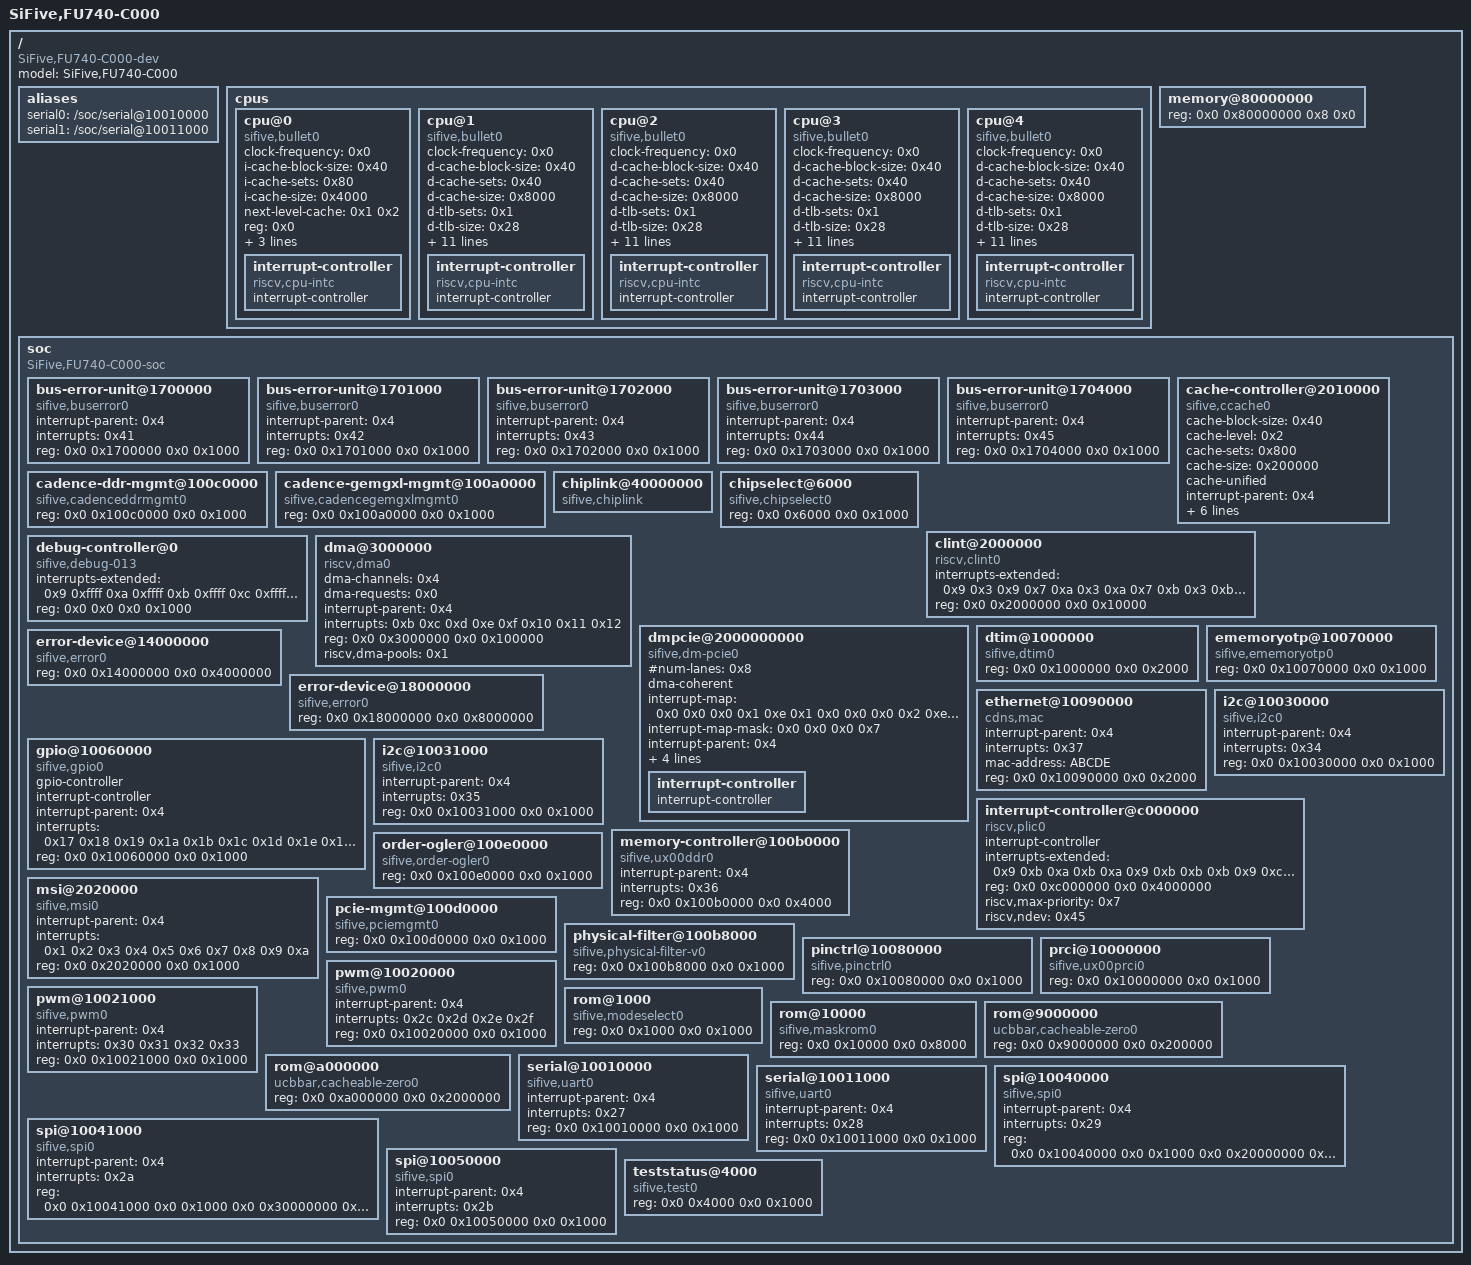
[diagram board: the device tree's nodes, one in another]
/dts-v1/;

/ {
	#address-cells = <0x2>;
	#size-cells = <0x2>;
	compatible = "SiFive,FU740-C000-dev", "fu700-dev", "sifive-dev";
	model = "SiFive,FU740-C000";

	aliases {
		serial0 = "/soc/serial@10010000";
		serial1 = "/soc/serial@10011000";
	};

	cpus {
		#address-cells = <0x1>;
		#size-cells = <0x0>;

		cpu@0 {
			clock-frequency = <0x0>;
			compatible = "sifive,bullet0", "riscv";
			device_type = "cpu";
			i-cache-block-size = <0x40>;
			i-cache-sets = <0x80>;
			i-cache-size = <0x4000>;
			next-level-cache = <0x1 0x2>;
			reg = <0x0>;
			riscv,isa = "rv64imac";
			sifive,dtim = <0x3>;
			status = "okay";
			timebase-frequency = <0xf4240>;

			interrupt-controller {
				#interrupt-cells = <0x1>;
				compatible = "riscv,cpu-intc";
				interrupt-controller;
				linux,phandle = <0x9>;
				phandle = <0x9>;
			};
		};

		cpu@1 {
			clock-frequency = <0x0>;
			compatible = "sifive,bullet0", "riscv";
			d-cache-block-size = <0x40>;
			d-cache-sets = <0x40>;
			d-cache-size = <0x8000>;
			d-tlb-sets = <0x1>;
			d-tlb-size = <0x28>;
			device_type = "cpu";
			i-cache-block-size = <0x40>;
			i-cache-sets = <0x80>;
			i-cache-size = <0x8000>;
			i-tlb-sets = <0x1>;
			i-tlb-size = <0x28>;
			mmu-type = "riscv,sv39";
			next-level-cache = <0x1 0x2>;
			reg = <0x1>;
			riscv,isa = "rv64imafdc";
			status = "okay";
			timebase-frequency = <0xf4240>;
			tlb-split;

			interrupt-controller {
				#interrupt-cells = <0x1>;
				compatible = "riscv,cpu-intc";
				interrupt-controller;
				linux,phandle = <0xa>;
				phandle = <0xa>;
			};
		};

		cpu@2 {
			clock-frequency = <0x0>;
			compatible = "sifive,bullet0", "riscv";
			d-cache-block-size = <0x40>;
			d-cache-sets = <0x40>;
			d-cache-size = <0x8000>;
			d-tlb-sets = <0x1>;
			d-tlb-size = <0x28>;
			device_type = "cpu";
			i-cache-block-size = <0x40>;
			i-cache-sets = <0x80>;
			i-cache-size = <0x8000>;
			i-tlb-sets = <0x1>;
			i-tlb-size = <0x28>;
			mmu-type = "riscv,sv39";
			next-level-cache = <0x1 0x2>;
			reg = <0x2>;
			riscv,isa = "rv64imafdc";
			status = "okay";
			timebase-frequency = <0xf4240>;
			tlb-split;

			interrupt-controller {
				#interrupt-cells = <0x1>;
				compatible = "riscv,cpu-intc";
				interrupt-controller;
				linux,phandle = <0xb>;
				phandle = <0xb>;
			};
		};

		cpu@3 {
			clock-frequency = <0x0>;
			compatible = "sifive,bullet0", "riscv";
			d-cache-block-size = <0x40>;
			d-cache-sets = <0x40>;
			d-cache-size = <0x8000>;
			d-tlb-sets = <0x1>;
			d-tlb-size = <0x28>;
			device_type = "cpu";
			i-cache-block-size = <0x40>;
			i-cache-sets = <0x80>;
			i-cache-size = <0x8000>;
			i-tlb-sets = <0x1>;
			i-tlb-size = <0x28>;
			mmu-type = "riscv,sv39";
			next-level-cache = <0x1 0x2>;
			reg = <0x3>;
			riscv,isa = "rv64imafdc";
			status = "okay";
			timebase-frequency = <0xf4240>;
			tlb-split;

			interrupt-controller {
				#interrupt-cells = <0x1>;
				compatible = "riscv,cpu-intc";
				interrupt-controller;
				linux,phandle = <0xc>;
				phandle = <0xc>;
			};
		};

		cpu@4 {
			clock-frequency = <0x0>;
			compatible = "sifive,bullet0", "riscv";
			d-cache-block-size = <0x40>;
			d-cache-sets = <0x40>;
			d-cache-size = <0x8000>;
			d-tlb-sets = <0x1>;
			d-tlb-size = <0x28>;
			device_type = "cpu";
			i-cache-block-size = <0x40>;
			i-cache-sets = <0x80>;
			i-cache-size = <0x8000>;
			i-tlb-sets = <0x1>;
			i-tlb-size = <0x28>;
			mmu-type = "riscv,sv39";
			next-level-cache = <0x1 0x2>;
			reg = <0x4>;
			riscv,isa = "rv64imafdc";
			status = "okay";
			timebase-frequency = <0xf4240>;
			tlb-split;

			interrupt-controller {
				#interrupt-cells = <0x1>;
				compatible = "riscv,cpu-intc";
				interrupt-controller;
				linux,phandle = <0xd>;
				phandle = <0xd>;
			};
		};
	};

	memory@80000000 {
		device_type = "memory";
		reg = <0x0 0x80000000 0x8 0x0>;
		linux,phandle = <0x8>;
		phandle = <0x8>;
	};

	soc {
		#address-cells = <0x2>;
		#size-cells = <0x2>;
		compatible = "SiFive,FU740-C000-soc", "fu700-soc", "sifive-soc", "simple-bus";
		ranges;

		bus-error-unit@1700000 {
			compatible = "sifive,buserror0";
			interrupt-parent = <0x4>;
			interrupts = <0x41>;
			reg = <0x0 0x1700000 0x0 0x1000>;
			reg-names = "control";
		};

		bus-error-unit@1701000 {
			compatible = "sifive,buserror0";
			interrupt-parent = <0x4>;
			interrupts = <0x42>;
			reg = <0x0 0x1701000 0x0 0x1000>;
			reg-names = "control";
		};

		bus-error-unit@1702000 {
			compatible = "sifive,buserror0";
			interrupt-parent = <0x4>;
			interrupts = <0x43>;
			reg = <0x0 0x1702000 0x0 0x1000>;
			reg-names = "control";
		};

		bus-error-unit@1703000 {
			compatible = "sifive,buserror0";
			interrupt-parent = <0x4>;
			interrupts = <0x44>;
			reg = <0x0 0x1703000 0x0 0x1000>;
			reg-names = "control";
		};

		bus-error-unit@1704000 {
			compatible = "sifive,buserror0";
			interrupt-parent = <0x4>;
			interrupts = <0x45>;
			reg = <0x0 0x1704000 0x0 0x1000>;
			reg-names = "control";
		};

		cache-controller@2010000 {
			cache-block-size = <0x40>;
			cache-level = <0x2>;
			cache-sets = <0x800>;
			cache-size = <0x200000>;
			cache-unified;
			compatible = "sifive,ccache0", "cache";
			interrupt-parent = <0x4>;
			interrupts = <0x13 0x14 0x15 0x16>;
			next-level-cache = <0x5 0x6 0x7 0x8>;
			reg = <0x0 0x2010000 0x0 0x1000 0x0 0x8000000 0x0 0x200000>;
			reg-names = "control", "sideband";
			sifive,ecc-granularity = <0x8>;
			sifive,mshr-count = <0xa>;
			linux,phandle = <0x2>;
			phandle = <0x2>;
		};

		cadence-ddr-mgmt@100c0000 {
			compatible = "sifive,cadenceddrmgmt0";
			reg = <0x0 0x100c0000 0x0 0x1000>;
			reg-names = "control";
		};

		cadence-gemgxl-mgmt@100a0000 {
			compatible = "sifive,cadencegemgxlmgmt0";
			reg = <0x0 0x100a0000 0x0 0x1000>;
			reg-names = "control";
		};

		chiplink@40000000 {
			#address-cells = <0x2>;
			#size-cells = <0x2>;
			compatible = "sifive,chiplink", "simple-bus";
			ranges = <0x18 0x0 0x18 0x0 0x8 0x0 0x0 0x40000000 0x0 0x40000000 0x0 0x20000000 0x10 0x0 0x10 0x0 0x8 0x0>;
			linux,phandle = <0x5>;
			phandle = <0x5>;
		};

		chipselect@6000 {
			compatible = "sifive,chipselect0";
			reg = <0x0 0x6000 0x0 0x1000>;
			reg-names = "control";
		};

		clint@2000000 {
			compatible = "riscv,clint0";
			interrupts-extended = <0x9 0x3 0x9 0x7 0xa 0x3 0xa 0x7 0xb 0x3 0xb 0x7 0xc 0x3 0xc 0x7 0xd 0x3 0xd 0x7>;
			reg = <0x0 0x2000000 0x0 0x10000>;
			reg-names = "control";
		};

		debug-controller@0 {
			compatible = "sifive,debug-013", "riscv,debug-013";
			interrupts-extended = <0x9 0xffff 0xa 0xffff 0xb 0xffff 0xc 0xffff 0xd 0xffff>;
			reg = <0x0 0x0 0x0 0x1000>;
			reg-names = "control";
		};

		dma@3000000 {
			#dma-cells = <0x1>;
			compatible = "riscv,dma0";
			dma-channels = <0x4>;
			dma-requests = <0x0>;
			interrupt-parent = <0x4>;
			interrupts = <0xb 0xc 0xd 0xe 0xf 0x10 0x11 0x12>;
			reg = <0x0 0x3000000 0x0 0x100000>;
			reg-names = "control";
			riscv,dma-pools = <0x1>;
		};

		dmpcie@2000000000 {
			#address-cells = <0x3>;
			#interrupt-cells = <0x1>;
			#num-lanes = <0x8>;
			#size-cells = <0x2>;
			compatible = "sifive,dm-pcie0", "snps,dw-pcie";
			device_type = "pci";
			dma-coherent;
			interrupt-map = <0x0 0x0 0x0 0x1 0xe 0x1 0x0 0x0 0x0 0x2 0xe 0x2 0x0 0x0 0x0 0x3 0xe 0x3 0x0 0x0 0x0 0x4 0xe 0x4>;
			interrupt-map-mask = <0x0 0x0 0x0 0x7>;
			interrupt-names = "msi", "inta", "intb", "intc", "intd";
			interrupt-parent = <0x4>;
			interrupts = <0x38 0x39 0x3a 0x3b 0x3c 0x3d 0x3e 0x3f 0x40>;
			reg = <0x20 0x0 0x20 0x0 0xe 0x0 0x1 0x0 0xd 0xf0000000 0x0 0x10000000 0x0 0x60000000 0x0 0x20000000>;
			reg-names = "pcieupper", "dbi", "config", "pcielower";

			interrupt-controller {
				#address-cells = <0x0>;
				#interrupt-cells = <0x1>;
				interrupt-controller;
				linux,phandle = <0xe>;
				phandle = <0xe>;
			};
		};

		dtim@1000000 {
			compatible = "sifive,dtim0";
			reg = <0x0 0x1000000 0x0 0x2000>;
			reg-names = "mem";
			linux,phandle = <0x3>;
			phandle = <0x3>;
		};

		ememoryotp@10070000 {
			compatible = "sifive,ememoryotp0";
			reg = <0x0 0x10070000 0x0 0x1000>;
			reg-names = "control";
		};

		error-device@14000000 {
			compatible = "sifive,error0";
			reg = <0x0 0x14000000 0x0 0x4000000>;
			linux,phandle = <0x6>;
			phandle = <0x6>;
		};

		error-device@18000000 {
			compatible = "sifive,error0";
			reg = <0x0 0x18000000 0x0 0x8000000>;
			linux,phandle = <0x1>;
			phandle = <0x1>;
		};

		ethernet@10090000 {
			compatible = "cdns,mac";
			interrupt-parent = <0x4>;
			interrupts = <0x37>;
			mac-address = "ABCDE";
			reg = <0x0 0x10090000 0x0 0x2000>;
			reg-names = "control";
		};

		gpio@10060000 {
			#gpio-cells = <0x2>;
			#interrupt-cells = <0x2>;
			compatible = "sifive,gpio0", "sifive,gpio1";
			gpio-controller;
			interrupt-controller;
			interrupt-parent = <0x4>;
			interrupts = <0x17 0x18 0x19 0x1a 0x1b 0x1c 0x1d 0x1e 0x1f 0x20 0x21 0x22 0x23 0x24 0x25 0x26>;
			reg = <0x0 0x10060000 0x0 0x1000>;
			reg-names = "control";
		};

		i2c@10030000 {
			compatible = "sifive,i2c0";
			interrupt-parent = <0x4>;
			interrupts = <0x34>;
			reg = <0x0 0x10030000 0x0 0x1000>;
			reg-names = "control";
		};

		i2c@10031000 {
			compatible = "sifive,i2c0";
			interrupt-parent = <0x4>;
			interrupts = <0x35>;
			reg = <0x0 0x10031000 0x0 0x1000>;
			reg-names = "control";
		};

		interrupt-controller@c000000 {
			#interrupt-cells = <0x1>;
			compatible = "riscv,plic0";
			interrupt-controller;
			interrupts-extended = <0x9 0xb 0xa 0xb 0xa 0x9 0xb 0xb 0xb 0x9 0xc 0xb 0xc 0x9 0xd 0xb 0xd 0x9>;
			reg = <0x0 0xc000000 0x0 0x4000000>;
			reg-names = "control";
			riscv,max-priority = <0x7>;
			riscv,ndev = <0x45>;
			linux,phandle = <0x4>;
			phandle = <0x4>;
		};

		memory-controller@100b0000 {
			compatible = "sifive,ux00ddr0";
			interrupt-parent = <0x4>;
			interrupts = <0x36>;
			reg = <0x0 0x100b0000 0x0 0x4000>;
			reg-names = "control";
		};

		msi@2020000 {
			compatible = "sifive,msi0";
			interrupt-parent = <0x4>;
			interrupts = <0x1 0x2 0x3 0x4 0x5 0x6 0x7 0x8 0x9 0xa>;
			reg = <0x0 0x2020000 0x0 0x1000>;
			reg-names = "control";
		};

		order-ogler@100e0000 {
			compatible = "sifive,order-ogler0";
			reg = <0x0 0x100e0000 0x0 0x1000>;
			reg-names = "control";
		};

		pcie-mgmt@100d0000 {
			compatible = "sifive,pciemgmt0";
			reg = <0x0 0x100d0000 0x0 0x1000>;
			reg-names = "control";
		};

		physical-filter@100b8000 {
			compatible = "sifive,physical-filter-v0";
			reg = <0x0 0x100b8000 0x0 0x1000>;
			reg-names = "control";
		};

		pinctrl@10080000 {
			compatible = "sifive,pinctrl0";
			reg = <0x0 0x10080000 0x0 0x1000>;
			reg-names = "control";
		};

		prci@10000000 {
			compatible = "sifive,ux00prci0";
			reg = <0x0 0x10000000 0x0 0x1000>;
			reg-names = "control";
		};

		pwm@10020000 {
			compatible = "sifive,pwm0";
			interrupt-parent = <0x4>;
			interrupts = <0x2c 0x2d 0x2e 0x2f>;
			reg = <0x0 0x10020000 0x0 0x1000>;
			reg-names = "control";
		};

		pwm@10021000 {
			compatible = "sifive,pwm0";
			interrupt-parent = <0x4>;
			interrupts = <0x30 0x31 0x32 0x33>;
			reg = <0x0 0x10021000 0x0 0x1000>;
			reg-names = "control";
		};

		rom@1000 {
			compatible = "sifive,modeselect0";
			reg = <0x0 0x1000 0x0 0x1000>;
			reg-names = "mem";
		};

		rom@10000 {
			compatible = "sifive,maskrom0";
			reg = <0x0 0x10000 0x0 0x8000>;
			reg-names = "mem";
		};

		rom@9000000 {
			compatible = "ucbbar,cacheable-zero0";
			reg = <0x0 0x9000000 0x0 0x200000>;
		};

		rom@a000000 {
			compatible = "ucbbar,cacheable-zero0";
			reg = <0x0 0xa000000 0x0 0x2000000>;
			linux,phandle = <0x7>;
			phandle = <0x7>;
		};

		serial@10010000 {
			compatible = "sifive,uart0";
			interrupt-parent = <0x4>;
			interrupts = <0x27>;
			reg = <0x0 0x10010000 0x0 0x1000>;
			reg-names = "control";
		};

		serial@10011000 {
			compatible = "sifive,uart0";
			interrupt-parent = <0x4>;
			interrupts = <0x28>;
			reg = <0x0 0x10011000 0x0 0x1000>;
			reg-names = "control";
		};

		spi@10040000 {
			#address-cells = <0x1>;
			#size-cells = <0x0>;
			compatible = "sifive,spi0";
			interrupt-parent = <0x4>;
			interrupts = <0x29>;
			reg = <0x0 0x10040000 0x0 0x1000 0x0 0x20000000 0x0 0x10000000>;
			reg-names = "control", "mem";
		};

		spi@10041000 {
			#address-cells = <0x1>;
			#size-cells = <0x0>;
			compatible = "sifive,spi0";
			interrupt-parent = <0x4>;
			interrupts = <0x2a>;
			reg = <0x0 0x10041000 0x0 0x1000 0x0 0x30000000 0x0 0x10000000>;
			reg-names = "control", "mem";
		};

		spi@10050000 {
			#address-cells = <0x1>;
			#size-cells = <0x0>;
			compatible = "sifive,spi0";
			interrupt-parent = <0x4>;
			interrupts = <0x2b>;
			reg = <0x0 0x10050000 0x0 0x1000>;
			reg-names = "control";
		};

		teststatus@4000 {
			compatible = "sifive,test0";
			reg = <0x0 0x4000 0x0 0x1000>;
			reg-names = "control";
		};
	};
};
